# ATSAM3U4E device description
Architecture: CORTEX-M3; Family: SAM3; Series: SAM3U
Registers are 32-bit, read-write, no defined reset value unless marked. A register's access mark holds for its fields unless they carry their own. Offsets are from the block's base; [hi:lo] are bit positions; {n}, {i} and the like mark numbered series.

## ADC — Analog-to-Digital Converter
Instances: ADC 0x400AC000
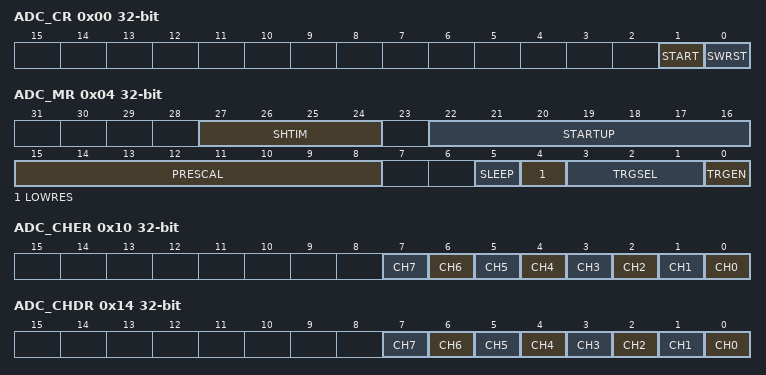
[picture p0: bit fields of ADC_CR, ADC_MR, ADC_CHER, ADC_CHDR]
0x00 ADC_CR wo — Control Register
  [1] START — Start Conversion
  [0] SWRST — Software Reset
0x04 ADC_MR — Mode Register
  [27:24] SHTIM — Sample & Hold Time
  [22:16] STARTUP — Start Up Time
  [15:8] PRESCAL — Prescaler Rate Selection
  [5] SLEEP — Sleep Mode
  [4] LOWRES — Resolution
  [3:1] TRGSEL — Trigger Selection
  [0] TRGEN — Trigger Enable
0x10 ADC_CHER wo — Channel Enable Register
  [n] CH{n} (n=0..7) — Channel {n} Enable
0x14 ADC_CHDR wo — Channel Disable Register
  [n] CH{n} (n=0..7) — Channel {n} Disable
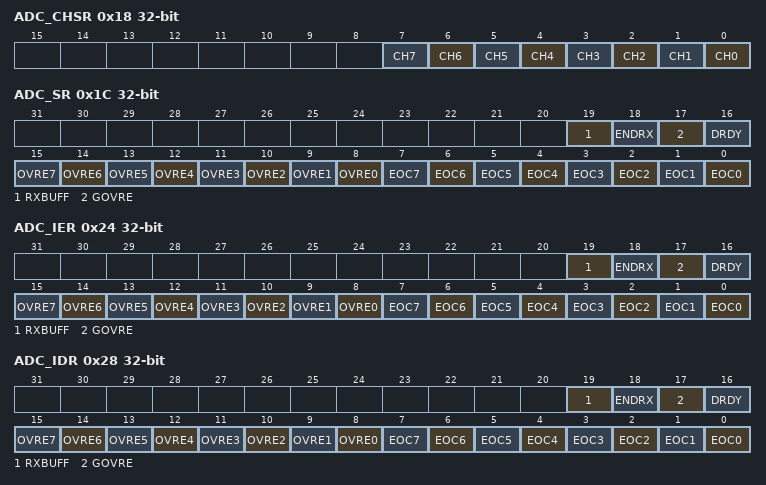
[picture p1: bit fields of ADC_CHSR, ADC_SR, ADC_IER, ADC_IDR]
0x18 ADC_CHSR ro — Channel Status Register
  [n] CH{n} (n=0..7) — Channel {n} Status
0x1C ADC_SR ro — Status Register
  [19] RXBUFF — RX Buffer Full
  [18] ENDRX — End of RX Buffer
  [17] GOVRE — General Overrun Error
  [16] DRDY — Data Ready
  [n+8] OVRE{n} (n=0..7) — Overrun Error {n}
  [n] EOC{n} (n=0..7) — End of Conversion {n}
0x20 ADC_LCDR ro — Last Converted Data Register
  [9:0] LDATA — Last Data Converted
0x24 ADC_IER wo — Interrupt Enable Register
  [19] RXBUFF — Receive Buffer Full Interrupt Enable
  [18] ENDRX — End of Receive Buffer Interrupt Enable
  [17] GOVRE — General Overrun Error Interrupt Enable
  [16] DRDY — Data Ready Interrupt Enable
  [n+8] OVRE{n} (n=0..7) — Overrun Error Interrupt Enable {n}
  [n] EOC{n} (n=0..7) — End of Conversion Interrupt Enable {n}
0x28 ADC_IDR wo — Interrupt Disable Register
  [19] RXBUFF — Receive Buffer Full Interrupt Disable
  [18] ENDRX — End of Receive Buffer Interrupt Disable
  [17] GOVRE — General Overrun Error Interrupt Disable
  [16] DRDY — Data Ready Interrupt Disable
  [n+8] OVRE{n} (n=0..7) — Overrun Error Interrupt Disable {n}
  [n] EOC{n} (n=0..7) — End of Conversion Interrupt Disable {n}
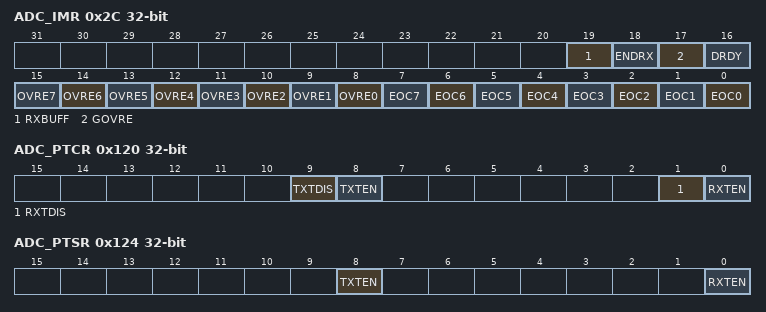
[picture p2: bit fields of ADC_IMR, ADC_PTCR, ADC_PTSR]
0x2C ADC_IMR ro — Interrupt Mask Register
  [19] RXBUFF — Receive Buffer Full Interrupt Mask
  [18] ENDRX — End of Receive Buffer Interrupt Mask
  [17] GOVRE — General Overrun Error Interrupt Mask
  [16] DRDY — Data Ready Interrupt Mask
  [n+8] OVRE{n} (n=0..7) — Overrun Error Interrupt Mask {n}
  [n] EOC{n} (n=0..7) — End of Conversion Interrupt Mask {n}
{0x30+4i} ADC_CDR{i} ro (i=0..7) — Channel Data Register {i}
  [9:0] DATA — Converted Data
0x100 ADC_RPR — Receive Pointer Register
  [31:0] RXPTR
0x104 ADC_RCR — Receive Counter Register
  [15:0] RXCTR
0x110 ADC_RNPR — Receive Next Pointer Register
  [31:0] RXNPTR — Receive Next Pointer
0x114 ADC_RNCR — Receive Next Counter Register
  [15:0] RXNCTR — Receive Next Counter
0x120 ADC_PTCR wo — Transfer Control Register
  [9] TXTDIS — Transmitter Transfer Disable
  [8] TXTEN — Transmitter Transfer Enable
  [1] RXTDIS — Receiver Transfer Disable
  [0] RXTEN — Receiver Transfer Enable
0x124 ADC_PTSR ro — Transfer Status Register
  [8] TXTEN — Transmitter Transfer Enable
  [0] RXTEN — Receiver Transfer Enable

## ADC12B — Analog-to-Digital Converter 12bits
Instances: ADC12B 0x400A8000
Registers as ADC (with ADC read as ADC12B); these are added or differ:
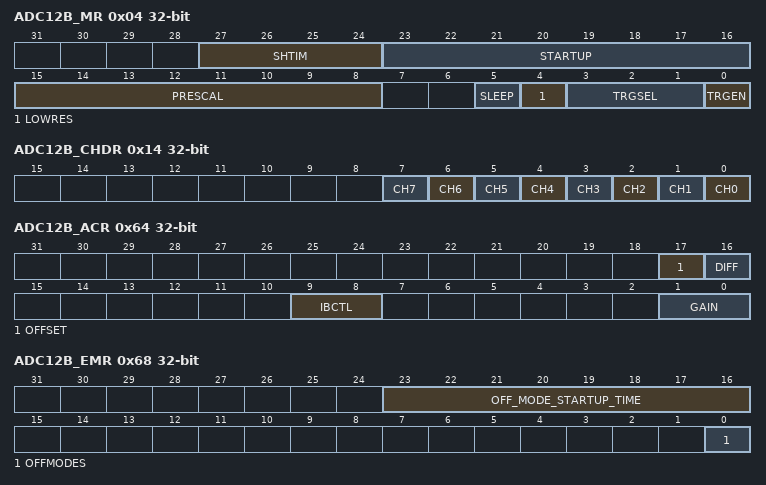
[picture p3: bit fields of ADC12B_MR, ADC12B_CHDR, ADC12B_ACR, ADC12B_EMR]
0x04 ADC12B_MR — Mode Register
  [27:24] SHTIM — Sample & Hold Time
  [23:16] STARTUP — Start Up Time
  [15:8] PRESCAL — Prescaler Rate Selection
  [5] SLEEP — Sleep Mode
  [4] LOWRES — Resolution
  [3:1] TRGSEL — Trigger Selection
  [0] TRGEN — Trigger Enable
0x14 ADC12B_CHDR wo — Channel Disable Register
  [n] CH{n} (n=0..7)
0x20 ADC12B_LCDR ro — Last Converted Data Register
  [11:0] LDATA — Last Data Converted
{0x30+4i} ADC12B_CDR{i} ro (i=0..7) — Channel Data Register {i}
  [11:0] DATA — Converted Data
0x64 ADC12B_ACR — Analog Control Register
  [17] OFFSET — Input OFFSET
  [16] DIFF — Differential Mode
  [9:8] IBCTL — Bias Current Control
  [1:0] GAIN — Input Gain
0x68 ADC12B_EMR — Extended Mode Register
  [23:16] OFF_MODE_STARTUP_TIME — Startup Time
  [0] OFFMODES — Off Mode if Sleep Bit (ADC12B_MR) = 1
